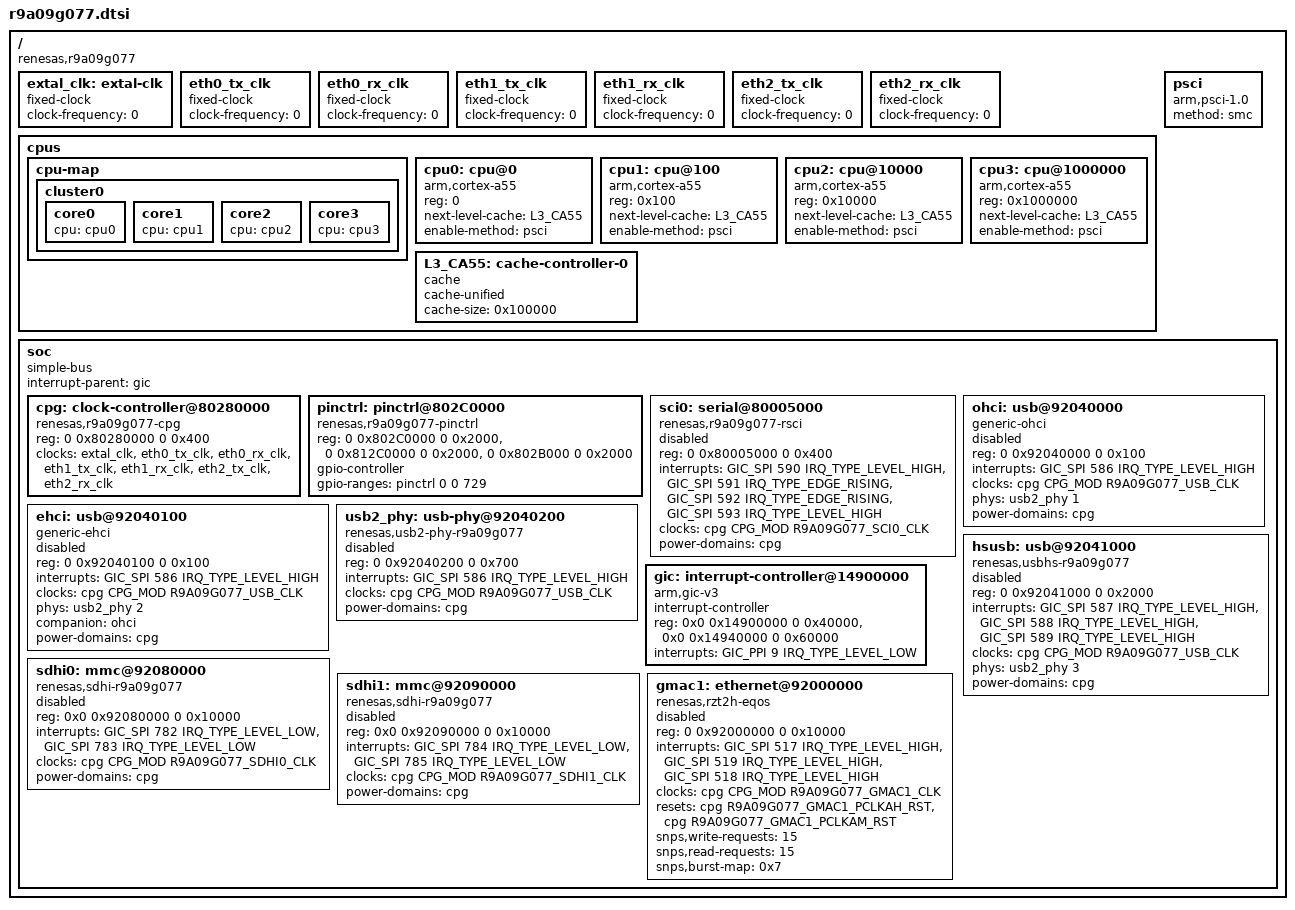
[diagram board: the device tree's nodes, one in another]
// SPDX-License-Identifier: (GPL-2.0-only OR BSD-2-Clause)
/*
 * Device Tree Source for the RZ/T2H SoC
 *
 * Copyright (C) 2023 Renesas Electronics Corp.
 */

#include <dt-bindings/interrupt-controller/arm-gic.h>
#include <dt-bindings/clock/r9a09g077-cpg.h>

/ {
	compatible = "renesas,r9a09g077";
	#address-cells = <2>;
	#size-cells = <2>;

	/* clock can be either from exclk or crystal oscillator (XIN/XOUT) */
	extal_clk: extal-clk {
		compatible = "fixed-clock";
		#clock-cells = <0>;
		/* This value must be overridden by the board */
		clock-frequency = <0>;
	};

	/* eth0_tx_clk clock input */
	eth0_tx_clk: eth0_tx_clk {
		compatible = "fixed-clock";
		#clock-cells = <0>;
		/* This value must be overridden by the board */
		clock-frequency = <0>;
	};

	/* eth0_rx_clk clock input */
	eth0_rx_clk: eth0_rx_clk {
		compatible = "fixed-clock";
		#clock-cells = <0>;
		/* This value must be overridden by the board */
		clock-frequency = <0>;
	};

	/* eth2_tx_clk clock input */
	eth1_tx_clk: eth1_tx_clk {
		compatible = "fixed-clock";
		#clock-cells = <0>;
		/* This value must be overridden by the board */
		clock-frequency = <0>;
	};

	/* eth1_rx_clk clock input */
	eth1_rx_clk: eth1_rx_clk {
		compatible = "fixed-clock";
		#clock-cells = <0>;
		/* This value must be overridden by the board */
		clock-frequency = <0>;
	};

	/* eth2_tx_clk clock input */
	eth2_tx_clk: eth2_tx_clk {
		compatible = "fixed-clock";
		#clock-cells = <0>;
		/* This value must be overridden by the board */
		clock-frequency = <0>;
	};

	/* eth2_rx_clk clock input */
	eth2_rx_clk: eth2_rx_clk {
		compatible = "fixed-clock";
		#clock-cells = <0>;
		/* This value must be overridden by the board */
		clock-frequency = <0>;
	};

	cpus {
		#address-cells = <1>;
		#size-cells = <0>;

		cpu-map {
			cluster0 {
				core0 {
					cpu = <&cpu0>;
				};
				core1 {
					cpu = <&cpu1>;
				};
				core2 {
					cpu = <&cpu2>;
				};
				core3 {
					cpu = <&cpu3>;
				};
			};
		};

		cpu0: cpu@0 {
			compatible = "arm,cortex-a55";
			reg = <0>;
			device_type = "cpu";
			next-level-cache = <&L3_CA55>;
			enable-method = "psci";
		};

		cpu1: cpu@100 {
			compatible = "arm,cortex-a55";
			reg = <0x100>;
			device_type = "cpu";
			next-level-cache = <&L3_CA55>;
			enable-method = "psci";
		};

		cpu2: cpu@10000 {
			compatible = "arm,cortex-a55";
			reg = <0x10000>;
			device_type = "cpu";
			next-level-cache = <&L3_CA55>;
			enable-method = "psci";
		};

		cpu3: cpu@1000000 {
			compatible = "arm,cortex-a55";
			reg = <0x1000000>;
			device_type = "cpu";
			next-level-cache = <&L3_CA55>;
			enable-method = "psci";
		};

		L3_CA55: cache-controller-0 {
			compatible = "cache";
			cache-unified;
			cache-size = <0x100000>;
		};
	};

	psci {
		compatible = "arm,psci-1.0", "arm,psci-0.2";
		method = "smc";
	};

	soc: soc {
		compatible = "simple-bus";
		interrupt-parent = <&gic>;
		#address-cells = <2>;
		#size-cells = <2>;
		ranges;

		cpg: clock-controller@80280000 {
			compatible = "renesas,r9a09g077-cpg";
			reg = <0 0x80280000 0 0x400>;
			clocks = <&extal_clk>,
				 <&eth0_tx_clk>, <&eth0_rx_clk>,
				 <&eth1_tx_clk>, <&eth1_rx_clk>,
				 <&eth2_tx_clk>, <&eth2_rx_clk>;
			clock-names = "extal",
				      "eth0_tx_clk", "eth0_rx_clk",
					  "eth1_tx_clk", "eth1_rx_clk",
				      "eth2_tx_clk", "eth2_rx_clk";
			#clock-cells = <2>;
			#reset-cells = <1>;
			#power-domain-cells = <0>;
		};

		pinctrl: pinctrl@802C0000 {
			compatible = "renesas,r9a09g077-pinctrl";
			reg = <0 0x802C0000 0 0x2000>,
			     <0 0x812C0000 0 0x2000>,
			     <0 0x802B000 0 0x2000>;
			reg-names = "port13_35","safety","non-safety";
			gpio-controller;
			#gpio-cells = <2>;
			gpio-ranges = <&pinctrl 0 0 729>;
		};

		sci0: serial@80005000 {
			compatible = "renesas,r9a09g077-rsci", "renesas,rsci";
			reg = <0 0x80005000 0 0x400>;
			interrupts = <GIC_SPI 590 IRQ_TYPE_LEVEL_HIGH>,
				     <GIC_SPI 591 IRQ_TYPE_EDGE_RISING>,
				     <GIC_SPI 592 IRQ_TYPE_EDGE_RISING>,
				     <GIC_SPI 593 IRQ_TYPE_LEVEL_HIGH>;
			interrupt-names = "eri", "rxi", "txi", "tei";
			clocks = <&cpg CPG_MOD R9A09G077_SCI0_CLK>;
			clock-names = "fck";
			power-domains = <&cpg>;
			status = "disabled";
		};

		ohci: usb@92040000 {
			compatible = "generic-ohci";
			reg = <0 0x92040000 0 0x100>;
			interrupts = <GIC_SPI 586 IRQ_TYPE_LEVEL_HIGH>;
			clocks = <&cpg CPG_MOD R9A09G077_USB_CLK>;
			phys = <&usb2_phy 1>;
			phy-names = "usb";
			power-domains = <&cpg>;
			status = "disabled";
		};

		ehci: usb@92040100 {
			compatible = "generic-ehci";
			reg = <0 0x92040100 0 0x100>;
			interrupts = <GIC_SPI 586 IRQ_TYPE_LEVEL_HIGH>;
			clocks = <&cpg CPG_MOD R9A09G077_USB_CLK>;
			phys = <&usb2_phy 2>;
			phy-names = "usb";
			companion = <&ohci>;
			power-domains = <&cpg>;
			status = "disabled";
		};

		usb2_phy: usb-phy@92040200 {
			compatible = "renesas,usb2-phy-r9a09g077";
			reg = <0 0x92040200 0 0x700>;
			interrupts = <GIC_SPI 586 IRQ_TYPE_LEVEL_HIGH>;
			clocks = <&cpg CPG_MOD R9A09G077_USB_CLK>;
			#phy-cells = <1>;
			power-domains = <&cpg>;
			status = "disabled";
		};

		hsusb: usb@92041000 {
			compatible = "renesas,usbhs-r9a09g077",
				     "renesas,rza2-usbhs";
			reg = <0 0x92041000 0 0x2000>;
			interrupts = <GIC_SPI 587 IRQ_TYPE_LEVEL_HIGH>,
				     <GIC_SPI 588 IRQ_TYPE_LEVEL_HIGH>,
				     <GIC_SPI 589 IRQ_TYPE_LEVEL_HIGH>;
			clocks = <&cpg CPG_MOD R9A09G077_USB_CLK>;
			phys = <&usb2_phy 3>;
			phy-names = "usb";
			power-domains = <&cpg>;
			status = "disabled";
		};

		gic: interrupt-controller@14900000 {
			compatible = "arm,gic-v3";
			#interrupt-cells = <3>;
			#address-cells = <0>;
			interrupt-controller;
			reg = <0x0 0x14900000 0 0x40000>,
			      <0x0 0x14940000 0 0x60000>;
			interrupts = <GIC_PPI 9 IRQ_TYPE_LEVEL_LOW>;
		};

		sdhi0: mmc@92080000  {
			compatible = "renesas,sdhi-r9a09g077",
				     "renesas,rcar-gen3-sdhi";
			reg = <0x0 0x92080000 0 0x10000>;
			interrupts = <GIC_SPI 782 IRQ_TYPE_LEVEL_LOW>,
				     <GIC_SPI 783 IRQ_TYPE_LEVEL_LOW>;
			clocks = <&cpg CPG_MOD R9A09G077_SDHI0_CLK>;
			clock-names = "clk";
			power-domains = <&cpg>;
			status = "disabled";
		};

		sdhi1: mmc@92090000 {
			compatible = "renesas,sdhi-r9a09g077",
				     "renesas,rcar-gen3-sdhi";
			reg = <0x0 0x92090000 0 0x10000>;
			interrupts = <GIC_SPI 784 IRQ_TYPE_LEVEL_LOW>,
				     <GIC_SPI 785 IRQ_TYPE_LEVEL_LOW>;
			clocks = <&cpg CPG_MOD R9A09G077_SDHI1_CLK>;
			clock-names = "clk";
			power-domains = <&cpg>;
			status = "disabled";
		};

		gmac1: ethernet@92000000 {
			compatible = "renesas,rzt2h-eqos",
				     "snps,dwc-qos-ethernet-4.10";
			reg = <0 0x92000000 0 0x10000>;
			interrupts = <GIC_SPI 517 IRQ_TYPE_LEVEL_HIGH>,
				     <GIC_SPI 519 IRQ_TYPE_LEVEL_HIGH>,
				     <GIC_SPI 518 IRQ_TYPE_LEVEL_HIGH>;
			interrupt-names = "macirq", "eth_wake_irq", "eth_lpi";
			clocks =  <&cpg CPG_MOD R9A09G077_GMAC1_CLK>;
			clock-names = "clk";
			resets = <&cpg R9A09G077_GMAC1_PCLKAH_RST>,
				 <&cpg R9A09G077_GMAC1_PCLKAM_RST>;
			reset-names = "reset_h", "reset_m";
			#address-cells = <1>;
			#size-cells = <0>;
			status = "disabled";
			snps,write-requests = <15>;
			snps,read-requests = <15>;
			snps,burst-map = <0x7>;
		};
	};
};

